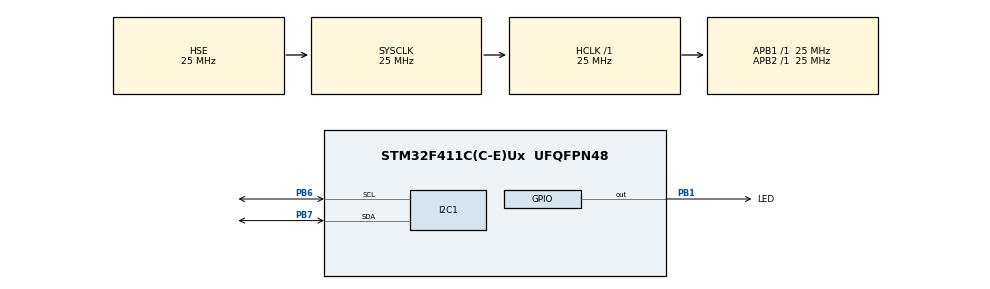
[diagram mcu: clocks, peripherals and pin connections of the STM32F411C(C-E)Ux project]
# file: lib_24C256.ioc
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Dma.I2C1_RX.1.Direction=DMA_PERIPH_TO_MEMORY
Dma.I2C1_RX.1.FIFOMode=DMA_FIFOMODE_DISABLE
Dma.I2C1_RX.1.Instance=DMA1_Stream0
Dma.I2C1_RX.1.MemDataAlignment=DMA_MDATAALIGN_BYTE
Dma.I2C1_RX.1.MemInc=DMA_MINC_ENABLE
Dma.I2C1_RX.1.Mode=DMA_NORMAL
Dma.I2C1_RX.1.PeriphDataAlignment=DMA_PDATAALIGN_BYTE
Dma.I2C1_RX.1.PeriphInc=DMA_PINC_DISABLE
Dma.I2C1_RX.1.Priority=DMA_PRIORITY_LOW
Dma.I2C1_TX.0.Direction=DMA_MEMORY_TO_PERIPH
Dma.I2C1_TX.0.FIFOMode=DMA_FIFOMODE_DISABLE
Dma.I2C1_TX.0.Instance=DMA1_Stream1
Dma.I2C1_TX.0.MemDataAlignment=DMA_MDATAALIGN_BYTE
Dma.I2C1_TX.0.MemInc=DMA_MINC_ENABLE
Dma.I2C1_TX.0.Mode=DMA_NORMAL
Dma.I2C1_TX.0.PeriphDataAlignment=DMA_PDATAALIGN_BYTE
Dma.I2C1_TX.0.PeriphInc=DMA_PINC_DISABLE
Dma.I2C1_TX.0.Priority=DMA_PRIORITY_LOW
Dma.Request0=I2C1_TX
Dma.Request1=I2C1_RX
I2C1.I2C_Mode=I2C_Fast
Mcu.Family=STM32F4
Mcu.Name=STM32F411C(C-E)Ux
Mcu.Package=UFQFPN48
NVIC.DMA1_Stream0_IRQn=true\:0\:0\:false\:false\:true\:false\:true\:true
NVIC.DMA1_Stream1_IRQn=true\:0\:0\:false\:false\:true\:false\:true\:true
NVIC.PriorityGroup=NVIC_PRIORITYGROUP_4
PA13.Mode=Serial_Wire
PA13.Signal=SYS_JTMS-SWDIO
PA14.Mode=Serial_Wire
PA14.Signal=SYS_JTCK-SWCLK
PB1.GPIO_Label=LED
PB1.Signal=GPIO_Output
PB6.GPIO_Pu=GPIO_PULLUP
PB6.Mode=I2C
PB6.Signal=I2C1_SCL
PB7.GPIO_Pu=GPIO_PULLUP
PB7.Mode=I2C
PB7.Signal=I2C1_SDA
PH0\ -\ OSC_IN.Mode=HSE-External-Oscillator
PH0\ -\ OSC_IN.Signal=RCC_OSC_IN
PH1\ -\ OSC_OUT.Mode=HSE-External-Oscillator
PH1\ -\ OSC_OUT.Signal=RCC_OSC_OUT
ProjectManager.HeapSize=0x200
ProjectManager.StackSize=0x400
ProjectManager.TargetToolchain=STM32CubeIDE
RCC.48MHZClocksFreq_Value=75000000
RCC.AHBFreq_Value=25000000
RCC.APB1Freq_Value=25000000
RCC.APB1TimFreq_Value=25000000
RCC.APB2Freq_Value=25000000
RCC.APB2TimFreq_Value=25000000
RCC.CortexFreq_Value=25000000
RCC.HCLKFreq_Value=25000000
RCC.HSE_VALUE=25000000
RCC.HSI_VALUE=16000000
RCC.LSE_VALUE=32768
RCC.PLLSourceVirtual=RCC_PLLSOURCE_HSE
RCC.SYSCLKFreq_VALUE=25000000
RCC.SYSCLKSource=RCC_SYSCLKSOURCE_HSE
RCC.VCOOutputFreq_Value=300000000
board=custom

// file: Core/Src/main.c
/* USER CODE BEGIN Header */
/**
  ******************************************************************************
  * @file           : main.c
  * @brief          : Main program body
  ******************************************************************************
  * @attention
  *
  * Copyright (c) 2023 STMicroelectronics.
  * All rights reserved.
  *
  * This software is licensed under terms that can be found in the LICENSE file
  * in the root directory of this software component.
  * If no LICENSE file comes with this software, it is provided AS-IS.
  *
  ******************************************************************************
  */
/* USER CODE END Header */
#include "main.h"
#include "dma.h"
#include "i2c.h"
#include "gpio.h"

/* USER CODE BEGIN Includes */
#include "usr/j3_lib_24C256.h"
/* USER CODE END Includes */

void SystemClock_Config(void);

/* USER CODE BEGIN 0 */

int8_t enviaDadosI2C(uint16_t _devEndereco, uint8_t * _pDados, uint16_t _tam)
{
	HAL_I2C_Master_Receive_DMA(&hi2c1, _devEndereco, _pDados, _tam);
	return 0;
}

int8_t recebDadosI2C(uint16_t _devEndereco, uint8_t * _pDados, uint16_t _tam)
{
	HAL_I2C_Master_Receive_DMA (&hi2c1, _devEndereco, _pDados, _tam);
	return 0;
}

extern enviaDados fnEnviaDados;
//fnRecebDados = recebDadosI2C;

/* USER CODE END 0 */

int main(void)
{
  /* USER CODE BEGIN 1 */
	const uint16_t LED_Tempo_ms = 1200;
	uint32_t auxTick = 0;
	uint32_t nowTick;

	j3_24C256_t *memPrincipal;

	fnEnviaDados = enviaDadosI2C;

	memPrincipal = j3_24c256_new(&hi2c1, 0xFF);
	//memPrincipal-> = ;
	//memPrincipal->
	j3_24c256_escreveDado(memPrincipal);

  /* USER CODE END 1 */

  /* MCU Configuration--------------------------------------------------------*/

  /* Reset of all peripherals, Initializes the Flash interface and the Systick. */
  HAL_Init();

  /* Configure the system clock */
  SystemClock_Config();

  /* Initialize all configured peripherals */
  MX_GPIO_Init();
  MX_DMA_Init();
  MX_I2C1_Init();

  /* Infinite loop */
  /* USER CODE BEGIN WHILE */
  while (1)
  {
    nowTick = HAL_GetTick();

    if(nowTick - auxTick >= LED_Tempo_ms)
    {
    	auxTick = nowTick;
    	HAL_GPIO_TogglePin(LED_GPIO_Port, LED_Pin);
    }

    /* USER CODE END WHILE */

  }
}

void SystemClock_Config(void)
{
  RCC_OscInitTypeDef RCC_OscInitStruct = {0};
  RCC_ClkInitTypeDef RCC_ClkInitStruct = {0};

  /** Configure the main internal regulator output voltage
  */
  __HAL_RCC_PWR_CLK_ENABLE();
  __HAL_PWR_VOLTAGESCALING_CONFIG(PWR_REGULATOR_VOLTAGE_SCALE1);

  /** Initializes the RCC Oscillators according to the specified parameters
  * in the RCC_OscInitTypeDef structure.
  */
  RCC_OscInitStruct.OscillatorType = RCC_OSCILLATORTYPE_HSE;
  RCC_OscInitStruct.HSEState = RCC_HSE_ON;
  RCC_OscInitStruct.PLL.PLLState = RCC_PLL_NONE;
  if (HAL_RCC_OscConfig(&RCC_OscInitStruct) != HAL_OK)
  {
    Error_Handler();
  }

  /** Initializes the CPU, AHB and APB buses clocks
  */
  RCC_ClkInitStruct.ClockType = RCC_CLOCKTYPE_HCLK|RCC_CLOCKTYPE_SYSCLK
                              |RCC_CLOCKTYPE_PCLK1|RCC_CLOCKTYPE_PCLK2;
  RCC_ClkInitStruct.SYSCLKSource = RCC_SYSCLKSOURCE_HSE;
  RCC_ClkInitStruct.AHBCLKDivider = RCC_SYSCLK_DIV1;
  RCC_ClkInitStruct.APB1CLKDivider = RCC_HCLK_DIV1;
  RCC_ClkInitStruct.APB2CLKDivider = RCC_HCLK_DIV1;

  if (HAL_RCC_ClockConfig(&RCC_ClkInitStruct, FLASH_LATENCY_0) != HAL_OK)
  {
    Error_Handler();
  }
}

void Error_Handler(void)
{
  __disable_irq();
  while (1)
  {
  }
}
